# nrf5340_application register map
Vendor: Nordic Semiconductor; Series: nrf53; File version: 1
CPU: CM33 r0p4, little endian, MPU, FPU, 3 interrupt priority bits, 69 interrupts
Registers are 32-bit, read-write, reset 0x0 unless marked. A register's access mark holds for its fields unless they carry their own. Offsets are from the block's base; [hi:lo] are bit positions.

## CC_DIN_S — CRYPTOCELL Data IN interface
Base 0x50845000; alternate view of CC_AES_S
0xC00 DIN_BUFFER wo — Used by CPU to write data directly to the DIN buffer, which is then sent to the cryptographic engines for processing.
  [31:0] DATA — This register is mapped into 8 addresses in order to enable a CPU burst.
0xC20 DIN_DMA_MEM_BUSY ro — Status register for DIN DMA engine activity when accessing memory.
  [0] STATUS — DIN memory DMA engine status.
    0=Idle (DIN memory DMA engine is idle); 1=Busy (DIN memory DMA engine is busy)
0xC28 SRC_MEM_ADDR wo — Data source address in memory.
  [31:0] ADDR — Source address in memory.
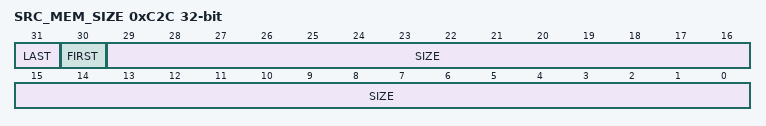
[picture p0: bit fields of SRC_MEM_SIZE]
0xC2C SRC_MEM_SIZE wo — The number of bytes to be read from memory. Writing to this register triggers the DMA operation.
  [31] LAST — This field is reserved
  [30] FIRST — This field is reserved
  [29:0] SIZE — Total number of bytes to read from memory.
0xC30 SRC_SRAM_ADDR — Data source address in RNG SRAM.
  [31:0] ADDR — Source address in RNG SRAM.
0xC34 SRC_SRAM_SIZE wo — The number of bytes to be read from RNG SRAM. Writing to this register triggers the DMA operation.
  [31:0] SIZE — Total number of bytes to read from RNG SRAM.
0xC38 DIN_DMA_SRAM_BUSY ro — Status register for DIN DMA engine activity when accessing RNG SRAM.
  [0] STATUS — DIN RNG SRAM DMA engine status.
    0=Idle (DIN RNG SRAM DMA engine is idle); 1=Busy (DIN RNG SRAM DMA engine is busy)
0xC3C DIN_DMA_SRAM_ENDIANNESS — Configure the endianness of DIN DMA transactions towards RNG SRAM.
  [0] ENDIAN — Endianness of DIN DMA transactions towards RNG SRAM. The default value is little-endian.
    0=LittleEndian (Use little-endian format for RNG SRAM DMA transactions); 1=BigEndian (Use big-endian format for RNG SRAM DMA transactions)
0xC44 DIN_SW_RESET wo — Reset the DIN DMA engine.
  [0] RESET — Writing any value to this address resets the DIN DMA engine. The reset takes 4 CPU clock cycles to complete.
    1=Enable (Reset DIN DMA engine.)
0xC48 DIN_CPU_DATA wo — Specifies the number of bytes the CPU will write to the DIN_BUFFER, ensuring the cryptographic engine processes the correct amount of data.
  [15:0] SIZE — When using CPU direct write to the DIN_BUFFER, the size of input data in bytes should be written to this register.
0xC4C DIN_WRITE_ALIGN wo — Indicates that the next CPU write to the DIN_BUFFER is the last in the sequence. This is needed only when the data size is NOT modulo 4 (e.g. HASH padding).
  [0] LAST — Next CPU write to the DIN_BUFFER is the last word.
    1=Confirm (The next CPU write is the last in the sequence.)
0xC50 DIN_FIFO_EMPTY ro reset 0x1 — Register indicating if DIN FIFO is empty and if more data can be accepted.
  [0] STATUS — DIN FIFO status
    0=NotEmpty (DIN FIFO is not empty); 1=Empty (DIN FIFO is empty, and more data can be accepted)
0xC58 DIN_FIFO_RESET wo — Reset the DIN FIFO, effectively clearing the FIFO for new data.
  [0] RESET — Writing any value to this address resets the DIN FIFO.
    1=Enable (Reset DIN FIFO.)

## CC_DOUT_S — CRYPTOCELL Data OUT interface
Base 0x50845000; alternate view of CC_AES_S
0xD00 DOUT_BUFFER ro — Cryptographic results directly accessible by the CPU.
  [31:0] DATA — This address can be used by the CPU to read data directly from the DOUT buffer.
0xD20 DOUT_DMA_MEM_BUSY ro — Status register for DOUT DMA engine activity when accessing memory.
  [0] STATUS — DOUT memory DMA engine status.
    0=Idle (DOUT memory DMA engine is idle); 1=Busy (DOUT memory DMA engine is busy)
0xD28 DST_MEM_ADDR wo — Data destination address in memory.
  [31:0] ADDR — Destination address in memory.
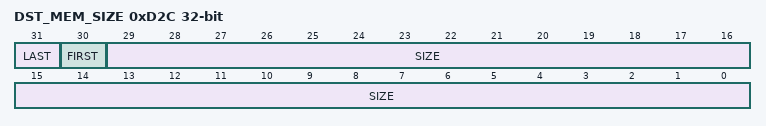
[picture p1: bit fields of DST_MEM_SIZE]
0xD2C DST_MEM_SIZE wo — The number of bytes to be written to memory.
  [31] LAST — This field is reserved
  [30] FIRST — This field is reserved
  [29:0] SIZE — Total number of bytes to write to memory.
0xD30 DST_SRAM_ADDR — Data destination address in RNG SRAM.
  [31:0] ADDR — Destination address in RNG SRAM.
0xD34 DST_SRAM_SIZE wo — The number of bytes to be written to RNG SRAM.
  [31:0] SIZE — Total number of bytes to write to RNG SRAM.
0xD38 DOUT_DMA_SRAM_BUSY ro — Status register for DOUT DMA engine activity when accessing RNG SRAM.
  [0] STATUS — DOUT RNG SRAM DMA engine status.
    0=Idle (DOUT RNG SRAM DMA engine is idle); 1=Busy (DOUT RNG SRAM DMA engine is busy)
0xD3C DOUT_DMA_SRAM_ENDIANNESS — Configure the endianness of DOUT DMA transactions towards RNG SRAM.
  [0] ENDIAN — Endianness of DOUT DMA transactions towards RNG SRAM. The default value is little-endian.
    0=LittleEndian (Use little-endian format for RNG SRAM DMA transactions); 1=BigEndian (Use big-endian format for RNG SRAM DMA transactions)
0xD44 DOUT_READ_ALIGN wo — Indication that the next CPU read from the DOUT_BUFFER is the last in the sequence. This is needed only when the data size is NOT modulo 4 (e.g. HASH padding).
  [0] LAST — Next CPU read from the DOUT_BUFFER is the last word, and the remaining read aligned content can be flushed.
    1=Flush the remaining read aligned content
0xD50 DOUT_FIFO_EMPTY ro reset 0x1 — Register indicating if DOUT FIFO is empty or if more data will come.
  [0] STATUS — DOUT FIFO status
    0=NotEmpty (DOUT FIFO is not empty, and more data will come); 1=Empty (DOUT FIFO is empty)
0xD58 DOUT_SW_RESET wo — Reset the DOUT DMA engine.
  [0] RESET — Writing any value to this address resets the DOUT DMA engine. The reset takes 4 CPU clock cycles to complete.
    1=Enable (Reset DOUT DMA engine.)
